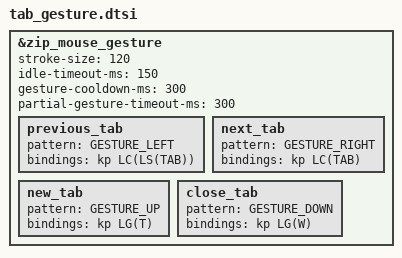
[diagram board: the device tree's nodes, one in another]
&zip_mouse_gesture {
    stroke-size = <120>;
    idle-timeout-ms = <150>;
    gesture-cooldown-ms = <300>;
    partial-gesture-timeout-ms = <300>;

    previous_tab {
        pattern = <GESTURE_LEFT>;
        bindings = <&kp LC(LS(TAB))>;
    };

    next_tab {
        pattern = <GESTURE_RIGHT>;
        bindings = <&kp LC(TAB)>;
    };

    new_tab {
        pattern = <GESTURE_UP>;
        bindings = <&kp LG(T)>;
    };

    close_tab {
        pattern = <GESTURE_DOWN>;
        bindings = <&kp LG(W)>;
    };
};
